# IWRL6432 register map
File version: 1.0
CPU: CM4 1.0, other endian, MPU, FPU, 3 interrupt priority bits
Registers are 32-bit, read-write, reset 0x0 unless marked. A register's access mark holds for its fields unless they carry their own. Offsets are from the block's base; [hi:lo] are bit positions.

## APP_HWA_ADCBUF_CTRL
Base 0x56080000
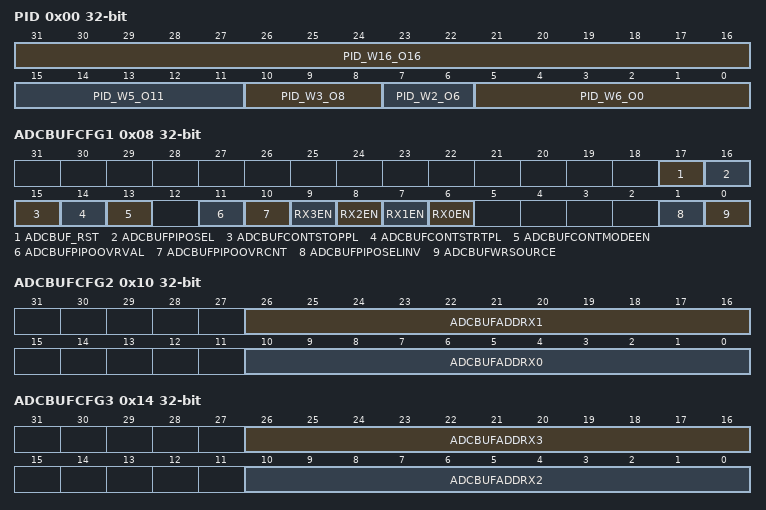
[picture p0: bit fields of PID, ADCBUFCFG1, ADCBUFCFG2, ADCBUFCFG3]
0x00 PID
  [31:16] PID_W16_O16, [15:11] PID_W5_O11, [10:8] PID_W3_O8, [7:6] PID_W2_O6, [5:0] PID_W6_O0
0x04 HW_REG0
  [31:0] HW_REG0 — [31:0] Reserved
0x08 ADCBUFCFG1
  [17] ADCBUF_RST — [17:17] Writing 1'b1 : Resets ADC BUFFER Control logic. Writing 1'b0: Releases the reset for ADC BUFFER control logic.
  [16] ADCBUFPIPOSEL — [16:16] TI Internal Feature Ping-pong select value from ADC Buffer Packing logic. Even in SW override mode, this register will indicate the ping-pong select signal generated from the ADC Buffer Packing logic and not the override value.
  [15] ADCBUFCONTSTOPPL — [15:15] Stop Pulse for Continuous mode. The data capture will stop once this register is set. Continous mode is expected to be only used for CZ and ADC Buffer Testpattern mode : Its a wspecial access type, write to this field will generate a pulse
  [14] ADCBUFCONTSTRTPL — [14:14] Start Pulse for Continuous mode. The data capture will start from Address 0 once this register is set. All the other configurations like Enable, Sample Count are expected to be programmed before this pulse. Continous mode is expected to be only used for CZ and ADC Buffer Testpattern mode : Its a wspecial access type, write to this field will generate a pulse
  [13] ADCBUFCONTMODEEN — [13:13] Continuous mode enable for ADC Buffer. This is set when a fixed number of samples have to be stored in Ping/Pong and not depend on Chirp time-lines (Eg: Analog Lab characterization to stream out continuous data from DFE). Continous mode is expected to be only used for CZ and ADC Buffer Testpattern mode
  [11] ADCBUFPIPOOVRVAL — [11:11] TI Internal Feature SW override value for ADC Buffer Ping Pong select
  [10] ADCBUFPIPOOVRCNT — [10:10] TI Internal Feature Override control for ADC Buffer Ping Pong select
  [9] RX3EN — [9:9] TI Reserved
  [8] RX2EN — [8:8] Enable for Rx2 write
  [7] RX1EN — [7:7] Enable for Rx1 write
  [6] RX0EN — [6:6] Enable for Rx0 write
  [1] ADCBUFPIPOSELINV — [1:1] TI Internal Feature Inversion control for ADC Buffer Ping-pong select. By default ADC Buffer write starts with Pong write. By setting this bit to 1, it will start from Ping write after reset.
  [0] ADCBUFWRSOURCE — [0:0] TI Internal Feature Write source for ADC Buffer. 0 --> DFE, 1 --> HWASS Interconnect
0x0C ADCBUFCFG1_EXTD
  [31:0] ADCBUFINTGENDLY — [31:0] TI Intenal Feature. No of clocks to delay the ping-pong switch and interrupt generation w.r.t ADC Valid fall pulse. This will enable dithering the DSP activity for successive ping-pong switch cycles. This will not delay the ping pong toggle which will happen immediately after ADC Valid fall.
0x10 ADCBUFCFG2
  [26:16] ADCBUFADDRX1 — [26:16] 128 bit Address offset to be added to the internal address pointer for Rx1 writes in Non-interleaved mode.
  [10:0] ADCBUFADDRX0 — [10:0] 128 bit Address offset to be added to the internal address pointer for Rx0 writes in Non-interleaved mode.
0x14 ADCBUFCFG3
  [26:16] ADCBUFADDRX3 — [26:16] TI Reserved
  [10:0] ADCBUFADDRX2 — [10:0] 128 bit Address offset to be added to the internal address pointer for Rx2 writes in Non-interleaved mode.
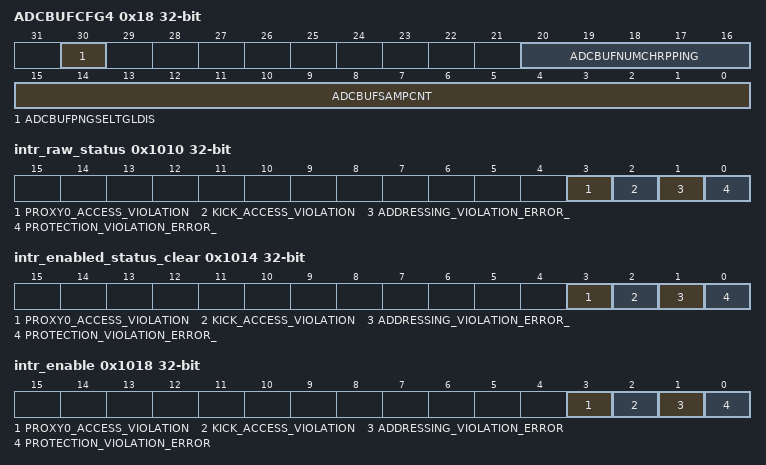
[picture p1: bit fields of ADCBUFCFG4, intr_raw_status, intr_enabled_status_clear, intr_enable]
0x18 ADCBUFCFG4
  [30] ADCBUFPNGSELTGLDIS — [30:30] TI Internal Feature 0 --> Delay Interrupt Gen and Ping/Pong toggle together based on cfg_interrupt_gen_delay, 1 --> Delay only Interrupt Gen based on cfg_interrupt_gen_delay. But toggle Ping/Pong select signal as soon as the write is complete.
  [20:16] ADCBUFNUMCHRPPING — [20:16] Number of chirps to be stored in Ping / Pong buffer. This register should be programmed with one less than the actual number needed.
  [15:0] ADCBUFSAMPCNT — [15:0] No of samples to store in each Ping and Pong register in continuous mode of ADC Buffer. In real only mode this refers to the number of real samples and in complex mode, this refers to number of complex samples. This refers to the number of samples per channel. This counter increments once for every new sample from DFE (as long as 1 or more channels are enabled). The max allowed value varies depending on other configurations (No of channels enabled and real/complex data). Continous mode is expected to be only used for CZ and ADC Buffer Testpattern mode
0x1C ADCBUFINTGENDITHERDLY
  [31:0] ADCBUFINTGENDITHERDLY — [31:0] TI Internal Feature. Additional dithering delay added on the Chirp Avilable interrupt
0x20 ADCBUFF_PING_MEM_INIT
  [0] mem_init — [0:0] Write_pulse bit field: Writing 1'b1 will start initialization of ADCBUFF PING Memory . Value in each row is initialized to 0x00_0000_0000
0x24 ADCBUFF_PING_MEM_DONE
  [0] mem_init_done — [0:0] This field will be high once initialization of ADCBUFF PING Memory is finished. Writing '1' would clear the bit.
0x28 ADCBUFF_PING_MEM_STATUS
  [0] mem_init_status — [0:0] 1'b0: No initialization is happening for ADCBUF PING Memory 1'b1: Initialization is in progress for ADCBUF PING Memory
0x2C ADCBUFF_PONG_MEM_INIT
  [0] mem_init — [0:0] Write_pulse bit field: Writing 1'b1 will start initialization of ADCBUF PONG Memory . Value in each row is initialized to 0x00_0000_0000
0x30 ADCBUFF_PONG_MEM_DONE
  [0] mem_init_done — [0:0] This field will be high once initialization of ADCBUF PONG Memory is finished. Writing '1' would clear the bit.
0x34 ADCBUFF_PONG_MEM_STATUS
  [0] mem_init_status — [0:0] 1'b0: No initialization is happening for ADCBUF PONG Memory 1'b1: Initialization is in progress for ADCBUF PONG Memory
0x38 HWASS_SHRD_RAM_MEM_INIT
  [0] mem_init — [0:0] Write_pulse bit field: Writing 1'b1 will start initialization of HWASS 160 kb shared memory bank . Value in each row is initialized to 0x00_0000_0000
0x3C HWASS_SHRD_RAM_MEM_DONE
  [0] mem_init_done — [0:0] This field will be high once initialization of HWASS 160 kb shared memory bank is finished. Writing '1' would clear the bit.
0x40 HWASS_SHRD_RAM_MEM_STATUS
  [0] mem_init_status — [0:0] 1'b0: No initialization is happening for HWASS 160kb shared memory bank 1'b1: Initialization is in progress for HWASS 160kb shared memory bank
0x44 HWASS_SHRD_RAM_ACCESS_ERROR_MASK
  [0] shmem_access_error_mask — [0:0] When 1'b1 : shared ram access error is masked. 1'b0 : shared ram access error is not masked.
0x48 HWASS_SHRD_RAM_ACCESS_ERROR_STATUS
  [0] shmem_access_error_status — [0:0] This field will be high whenever the invalid address of shared memory is accessed and the interrupt is not masked.
0x4C HWASS_SHRD_RAM_ACCESS_ERROR_STATUS_RAW
  [0] shmem_access_errror_status_raw — [0:0] Indicates the shared ram access error (raw status). Set irrespective of HWASS_SHRD_RAM_ACCESS_ERROR_MASK bit
0x50 HWASS_EDMA_CLOCK_GATE_CONTROL
  [2:0] hwa_edma_clock_gating_en — [2:0] Writing 3'b111 will gate the clock to HWA EDMA.Writing 3'b000 will ungate the clock
0x54 HWASS_RAM_160KB_CLOCK_GATE
  [2:0] enable — [2:0] 3'b000 : Ungate clock to 160KB RAM 3'b111 : Gate Clock to 160KB RAM
0x1008 LOCK0_KICK0 — - KICK0 component
  [31:0] KICK0_COMPONENT — [31:0] - KICK0 component
0x100C LOCK0_KICK1 — - KICK1 component
  [31:0] KICK1_COMPONENT — [31:0] - KICK1 component
0x1010 intr_raw_status — Interrupt Raw Status/Set Register
  [3] PROXY0_ACCESS_VIOLATION — [3:3] Proxy0 access violation error. Raw status is read. Write a 1 to set the status. Writing a 0 has no effect.
  [2] KICK_ACCESS_VIOLATION — [2:2] Kick access violation error. Raw status is read. Write a 1 to set the status. Writing a 0 has no effect.
  [1] ADDRESSING_VIOLATION_ERROR_ — [1:1] Addressing violation error. Raw status is read. Write a 1 to set the status. Writing a 0 has no effect.
  [0] PROTECTION_VIOLATION_ERROR_ — [0:0] Protection violation error. Raw status is read. Write a 1 to set the status. Writing a 0 has no effect.
0x1014 intr_enabled_status_clear — Interrupt Enabled Status/Clear register
  [3] PROXY0_ACCESS_VIOLATION — [3:3] Proxy0 access violation error. Enabled status is read. Write a 1 to clear the status. Writing a 0 has no effect.
  [2] KICK_ACCESS_VIOLATION — [2:2] Kick access violation error. Enabled status is read. Write a 1 to clear the status. Writing a 0 has no effect.
  [1] ADDRESSING_VIOLATION_ERROR_ — [1:1] Addressing violation error. Enabled status is read. Write a 1 to clear the status. Writing a 0 has no effect.
  [0] PROTECTION_VIOLATION_ERROR_ — [0:0] Protection violation error. Enabled status is read. Write a 1 to clear the status. Writing a 0 has no effect.
0x1018 intr_enable — Interrupt Enable register
  [3] PROXY0_ACCESS_VIOLATION — [3:3] Proxy0 access violation error enable. Write a 1 to set the enable. Writing a 0 has no effect.
  [2] KICK_ACCESS_VIOLATION — [2:2] Kick access violation error enable. Write a 1 to set the enable. Writing a 0 has no effect.
  [1] ADDRESSING_VIOLATION_ERROR — [1:1] Addressing violation error enable. Write a 1 to set the enable. Writing a 0 has no effect.
  [0] PROTECTION_VIOLATION_ERROR — [0:0] Protection violation error enable. Write a 1 to set the enable. Writing a 0 has no effect.
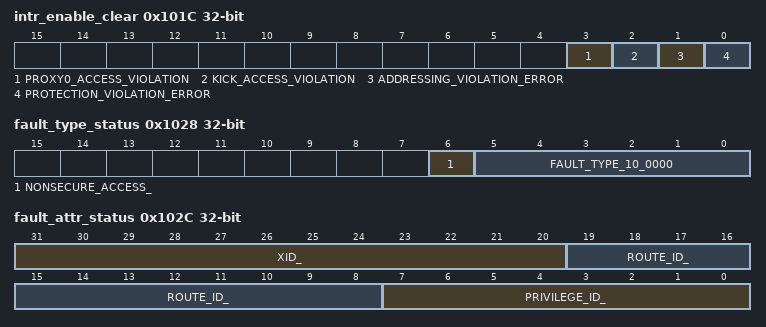
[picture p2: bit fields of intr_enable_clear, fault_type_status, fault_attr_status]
0x101C intr_enable_clear — Interrupt Enable Clear register
  [3] PROXY0_ACCESS_VIOLATION — [3:3] Proxy0 access violation error enable clear. Write a 1 to clear the enable. Writing a 0 has no effect.
  [2] KICK_ACCESS_VIOLATION — [2:2] Kick access violation error enable clear. Write a 1 to clear the enable. Writing a 0 has no effect.
  [1] ADDRESSING_VIOLATION_ERROR — [1:1] Addressing violation error enable clear. Write a 1 to clear the enable. Writing a 0 has no effect.
  [0] PROTECTION_VIOLATION_ERROR — [0:0] Protection violation error enable clear. Write a 1 to clear the enable. Writing a 0 has no effect.
0x1020 eoi
  [7:0] EOI_VECTOR_VALUE_ — [7:0] EOI vector value. Write this with interrupt distribution value in the chip.
0x1024 fault_address
  [31:0] FAULT_ADDRESS_ — [31:0] Fault Address.
0x1028 fault_type_status
  [6] NONSECURE_ACCESS_ — [6:6] Non-secure access.
  [5:0] FAULT_TYPE_10_0000 — [5:0] Fault Type 10_0000 = Supervisor read fault - priv = 1 dir = 1 dtype != 1 01_0000 = Supervisor write fault - priv = 1 dir = 0 00_1000 = Supervisor execute fault - priv = 1 dir = 1 dtype = 1 00_0100 = User read fault - priv = 0 dir = 1 dtype = 1 00_0010 = User write fault - priv = 0 dir = 0 00_0001 = User execute fault - priv = 0 dir = 1 dtype = 1 00_0000 = No fault
0x102C fault_attr_status — Fault Attribute Status register
  [31:20] XID_ — [31:20] XID.
  [19:8] ROUTE_ID_ — [19:8] Route ID.
  [7:0] PRIVILEGE_ID_ — [7:0] Privilege ID.
0x1030 fault_clear
  [0] FAULT_CLEAR__WRITING — [0:0] Fault clear. Writing a 1 clears the current fault. Writing a 0 has no effect.
